# STM32G0C1 register map
File version: 1.0
CPU: CM0 r0p1, little endian, MPU, no FPU, 4 interrupt priority bits
Registers are 32-bit, read-write, reset 0x0 unless marked. A register's access mark holds for its fields unless they carry their own. Offsets are from the block's base; [hi:lo] are bit positions.

## IWDG — Independent watchdog
Base 0x40003000
0x00 IWDG_KR wo — Key register
  [15:0] KEY — Key value (write only, read 0x0000)
0x04 IWDG_PR — Prescaler register
  [2:0] PR — Prescaler divider These bits are write access protected see . They are written by software to select the prescaler divider feeding the counter clock. PVU bit of the must be reset in order to be able to change the prescaler divider. Note: Reading this register returns the prescaler value from the VDD voltage domain. This value may not be up to date/valid if a write operation to this register is ongoing. For this reason the value read from this register is valid only when the PVU bit in the status register (IWDG_SR) is reset.
    0=divider /4; 1=divider /8; 2=divider /16; 3=divider /32; 4=divider /64; 5=divider /128; 6=divider /256; 7=divider /256
0x08 IWDG_RLR reset 0xFFF — Reload register
  [11:0] RL — Watchdog counter reload value
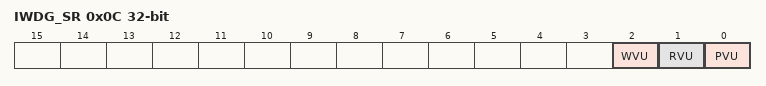
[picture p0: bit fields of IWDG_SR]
0x0C IWDG_SR ro — Status register
  [2] WVU — Watchdog counter window value update This bit is set by hardware to indicate that an update of the window value is ongoing. It is reset by hardware when the reload value update operation is completed in the VDD voltage domain (takes up to five LSI cycles). Window value can be updated only when WVU bit is reset.
  [1] RVU — Watchdog counter reload value update This bit is set by hardware to indicate that an update of the reload value is ongoing. It is reset by hardware when the reload value update operation is completed in the VDD voltage domain (takes up to five LSI cycles). Reload value can be updated only when RVU bit is reset.
  [0] PVU — Watchdog prescaler value update This bit is set by hardware to indicate that an update of the prescaler value is ongoing. It is reset by hardware when the prescaler update operation is completed in the VDD voltage domain (takes up to five LSI cycles). Prescaler value can be updated only when PVU bit is reset.
0x10 IWDG_WINR reset 0xFFF — Window register
  [11:0] WIN — Watchdog counter window value

## VREFBUF — System configuration controller
Base 0x40010030
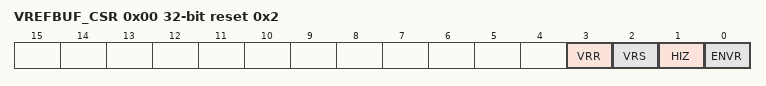
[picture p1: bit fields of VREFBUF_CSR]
0x00 VREFBUF_CSR access per field reset 0x2 — VREFBUF control and status register
  [3] VRR ro — Voltage reference buffer ready
    0=the voltage reference buffer output is not ready; 1=the voltage reference buffer output reached the requested level
  [2] VRS rw — Voltage reference scale This bit selects the value generated by the voltage reference buffer.
    0=Voltage reference set to VREF_OUT1 (around 2.048 V); 1=Voltage reference set to VREF_OUT2 (around 2.5 V)
  [1] HIZ rw — High impedance mode This bit controls the analog switch to connect or not the VREF+ pin. Refer to for the mode descriptions depending on ENVR bit configuration.
    0=VREF+ pin is internally connected to the voltage reference buffer output; 1=VREF+ pin is high impedance
  [0] ENVR rw — Voltage reference buffer mode enable This bit is used to enable the voltage reference buffer mode.
    0=Internal voltage reference mode disable (external voltage reference mode); 1=Internal voltage reference mode (reference buffer enable or hold mode) enable
0x04 VREFBUF_CCR — VREFBUF calibration control register
  [5:0] TRIM — Trimming code These bits are automatically initialized after reset with the trimming value stored in the Flash memory during the production test. Writing into these bits allows the tuning of the internal reference buffer voltage.

## WWDG — System window watchdog
Base 0x40002C00
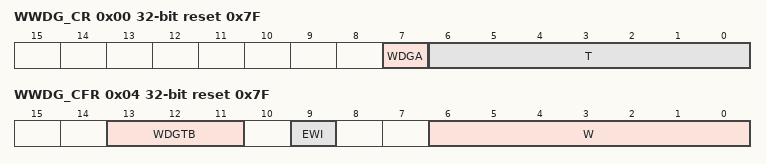
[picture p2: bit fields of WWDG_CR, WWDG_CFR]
0x00 WWDG_CR reset 0x7F — Control register
  [7] WDGA — Activation bit This bit is set by software and only cleared by hardware after a reset. When WDGAÂ =Â 1, the watchdog can generate a reset.
    0=Watchdog disabled; 1=Watchdog enabled
  [6:0] T — 7-bit counter (MSB to LSB) These bits contain the value of the watchdog counter, decremented every (4096 x 2WDGTB[1:0]) PCLK cycles. A reset is produced when it is decremented from 0x40 to 0x3F (T6 becomes cleared).
0x04 WWDG_CFR reset 0x7F — Configuration register
  [13:11] WDGTB — Timer base The timebase of the prescaler can be modified as follows:
    0=CK Counter Clock (PCLK div 4096) div 1; 1=CK Counter Clock (PCLK div 4096) div 2; 2=CK Counter Clock (PCLK div 4096) div 4; 3=CK Counter Clock (PCLK div 4096) div 8; 4=CK Counter Clock (PCLK div 4096) div 16; 5=CK Counter Clock (PCLK div 4096) div 32; 6=CK Counter Clock (PCLK div 4096) div 64; 7=CK Counter Clock (PCLK div 4096) div 128
  [9] EWI — Early wakeup interrupt When set, an interrupt occurs whenever the counter reaches the value 0x40. This interrupt is only cleared by hardware after a reset.
  [6:0] W — 7-bit window value These bits contain the window value to be compared with the down-counter.
0x08 WWDG_SR — Status register
  [0] EWIF — Early wakeup interrupt flag
